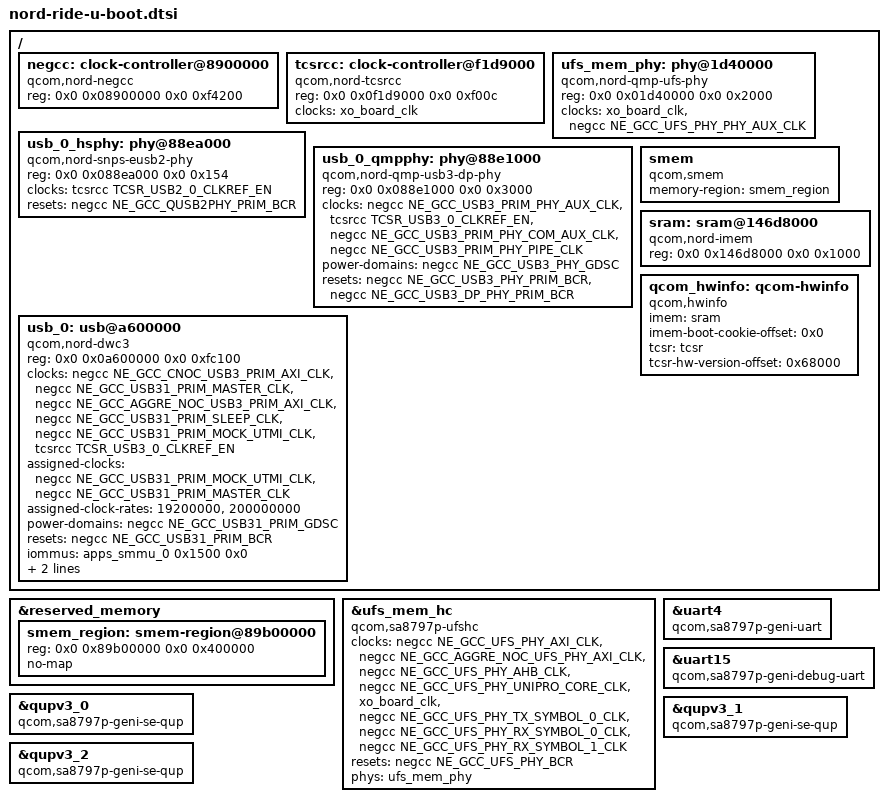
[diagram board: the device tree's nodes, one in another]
// SPDX-License-Identifier: BSD-3-Clause
/*
 * Copyright (c) Qualcomm Technologies, Inc. and/or its subsidiaries.
 */

#include <dt-bindings/clock/qcom,nord-negcc.h>
#include <dt-bindings/clock/qcom,nord-tcsrcc.h>

/ {
	negcc: clock-controller@8900000 {
		compatible = "qcom,nord-negcc";
		reg = <0x0 0x08900000 0x0 0xf4200>;
		#clock-cells = <1>;
		#reset-cells = <1>;
		#power-domain-cells = <1>;
	};

	tcsrcc: clock-controller@f1d9000 {
		compatible = "qcom,nord-tcsrcc",
			     "syscon";
		reg = <0x0 0x0f1d9000 0x0 0xf00c>;
		clocks = <&xo_board_clk>;
		#clock-cells = <1>;
		#reset-cells = <1>;
		bootph-all;
	};

	ufs_mem_phy: phy@1d40000 {
		compatible = "qcom,nord-qmp-ufs-phy",
			     "qcom,sm8650-qmp-ufs-phy";
		reg = <0x0 0x01d40000 0x0 0x2000>;

		clocks = <&xo_board_clk>,
			 <&negcc NE_GCC_UFS_PHY_PHY_AUX_CLK>;
		clock-names = "ref",
			      "ref_aux";

		#clock-cells = <1>;
		#phy-cells = <0>;

		status = "okay";
	};

	/* eUSB2 HS PHY for usb_0. Reset via NE_GCC_QUSB2PHY_PRIM_BCR. */
	usb_0_hsphy: phy@88ea000 {
		compatible = "qcom,nord-snps-eusb2-phy",
			     "qcom,sm8550-snps-eusb2-phy";
		reg = <0x0 0x088ea000 0x0 0x154>;
		#phy-cells = <0>;

		clocks = <&tcsrcc TCSR_USB2_0_CLKREF_EN>;
		clock-names = "ref";

		resets = <&negcc NE_GCC_QUSB2PHY_PRIM_BCR>;

		status = "okay";
	};

	usb_0_qmpphy: phy@88e1000 {
		compatible = "qcom,nord-qmp-usb3-dp-phy",
			     "qcom,x1e80100-qmp-usb3-dp-phy";
		reg = <0x0 0x088e1000 0x0 0x3000>;

		clocks = <&negcc NE_GCC_USB3_PRIM_PHY_AUX_CLK>,
			 <&tcsrcc TCSR_USB3_0_CLKREF_EN>,
			 <&negcc NE_GCC_USB3_PRIM_PHY_COM_AUX_CLK>,
			 <&negcc NE_GCC_USB3_PRIM_PHY_PIPE_CLK>;
		clock-names = "aux",
			      "ref",
			      "com_aux",
			      "usb3_pipe";

		power-domains = <&negcc NE_GCC_USB3_PHY_GDSC>;

		resets = <&negcc NE_GCC_USB3_PHY_PRIM_BCR>,
			 <&negcc NE_GCC_USB3_DP_PHY_PRIM_BCR>;
		reset-names = "phy",
			      "common";

		#clock-cells = <1>;
		#phy-cells = <1>;

		status = "okay";
	};

	usb_0: usb@a600000 {
		compatible = "qcom,nord-dwc3",
			     "qcom,snps-dwc3";
		reg = <0x0 0x0a600000 0x0 0xfc100>;

		clocks = <&negcc NE_GCC_CNOC_USB3_PRIM_AXI_CLK>,
			 <&negcc NE_GCC_USB31_PRIM_MASTER_CLK>,
			 <&negcc NE_GCC_AGGRE_NOC_USB3_PRIM_AXI_CLK>,
			 <&negcc NE_GCC_USB31_PRIM_SLEEP_CLK>,
			 <&negcc NE_GCC_USB31_PRIM_MOCK_UTMI_CLK>,
			 <&tcsrcc TCSR_USB3_0_CLKREF_EN>;
		clock-names = "cfg_noc",
			      "core",
			      "iface",
			      "sleep",
			      "mock_utmi",
			      "xo";

		assigned-clocks = <&negcc NE_GCC_USB31_PRIM_MOCK_UTMI_CLK>,
				  <&negcc NE_GCC_USB31_PRIM_MASTER_CLK>;
		assigned-clock-rates = <19200000>, <200000000>;

		power-domains = <&negcc NE_GCC_USB31_PRIM_GDSC>;

		resets = <&negcc NE_GCC_USB31_PRIM_BCR>;

		iommus = <&apps_smmu_0 0x1500 0x0>;

		phys = <&usb_0_hsphy>, <&usb_0_qmpphy 0>;
		phy-names = "usb2-phy", "usb3-phy";

		dr_mode = "peripheral";
		status = "okay";
		bootph-all;
	};

	smem {
		compatible = "qcom,smem";
		memory-region = <&smem_region>;
	};

	sram: sram@146d8000 {
		compatible = "qcom,nord-imem", "syscon", "simple-mfd";
		reg = <0x0 0x146d8000 0x0 0x1000>;
		ranges = <0x0 0x0 0x146d8000 0x1000>;

		#address-cells = <1>;
		#size-cells = <1>;
	};

	/* IMEM boot cookie + TCSR HW version offsets */
	qcom_hwinfo: qcom-hwinfo {
		compatible = "qcom,hwinfo";

		imem = <&sram>;
		imem-boot-cookie-offset = <0x0>;

		tcsr = <&tcsr>;
		tcsr-hw-version-offset = <0x68000>;
	};

};

&reserved_memory {
	smem_region: smem-region@89b00000 {
		reg = <0x0 0x89b00000 0x0 0x400000>;
		no-map;
	};
};

&ufs_mem_hc {
	compatible = "qcom,sa8797p-ufshc",
		     "qcom,sa8255p-ufshc",
		     "qcom,ufshc";

	clocks = <&negcc NE_GCC_UFS_PHY_AXI_CLK>,
		 <&negcc NE_GCC_AGGRE_NOC_UFS_PHY_AXI_CLK>,
		 <&negcc NE_GCC_UFS_PHY_AHB_CLK>,
		 <&negcc NE_GCC_UFS_PHY_UNIPRO_CORE_CLK>,
		 <&xo_board_clk>,
		 <&negcc NE_GCC_UFS_PHY_TX_SYMBOL_0_CLK>,
		 <&negcc NE_GCC_UFS_PHY_RX_SYMBOL_0_CLK>,
		 <&negcc NE_GCC_UFS_PHY_RX_SYMBOL_1_CLK>;
	clock-names = "core_clk",
		      "bus_aggr_clk",
		      "iface_clk",
		      "core_clk_unipro",
		      "ref_clk",
		      "tx_lane0_sync_clk",
		      "rx_lane0_sync_clk",
		      "rx_lane1_sync_clk";

	resets = <&negcc NE_GCC_UFS_PHY_BCR>;
	reset-names = "rst";

	phys = <&ufs_mem_phy>;
	phy-names = "ufsphy";
};

&uart4 {
	compatible = "qcom,sa8797p-geni-uart",
		     "qcom,sa8255p-geni-uart",
		     "qcom,geni-uart";
};

&uart15 {
	compatible = "qcom,sa8797p-geni-debug-uart",
		     "qcom,sa8255p-geni-debug-uart",
		     "qcom,geni-debug-uart";
};

&qupv3_0 {
	compatible = "qcom,sa8797p-geni-se-qup",
		     "qcom,sa8255p-geni-se-qup",
		     "qcom,geni-se-qup";
};

&qupv3_1 {
	compatible = "qcom,sa8797p-geni-se-qup",
		     "qcom,sa8255p-geni-se-qup",
		     "qcom,geni-se-qup";
};

&qupv3_2 {
	compatible = "qcom,sa8797p-geni-se-qup",
		     "qcom,sa8255p-geni-se-qup",
		     "qcom,geni-se-qup";
};
